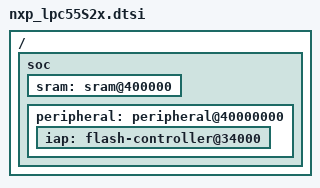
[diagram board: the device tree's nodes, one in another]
/*
 * Copyright (c) 2020 Lemonbeat GmbH
 *
 * SPDX-License-Identifier: Apache-2.0
 */

#include <mem.h>
#include <arm/armv8-m.dtsi>
#include <zephyr/dt-bindings/gpio/gpio.h>
#include <zephyr/dt-bindings/i2c/i2c.h>

/ {
	soc {
		sram: sram@400000 {
			ranges = <0x4000000 0x4000000 0x20000000>;
		};

		peripheral: peripheral@40000000 {
			ranges = <0x0 0x40000000 0x10000000>;

			iap: flash-controller@34000 {
				ranges = <0x0 0x10000000 0x3020000>;
			};
		};
	};
};

#include "nxp_lpc55S2x_common.dtsi"

/*
 * Explicitly enable IAP after we include the common LPC55S6X dtsi file,
 * which will set it to disabled.
 */
&iap {
	status = "okay";
};
